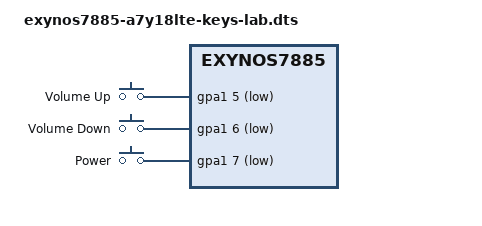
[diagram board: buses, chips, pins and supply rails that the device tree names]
// SPDX-License-Identifier: GPL-2.0
/*
 * Samsung A7 2018 Exynos7885 GPIO key mapping syntax-only research.
 *
 * All rev00/01/03 historical a7y18lte trees include the common
 * pinctrl gpa1-5 (volume up), gpa1-6 (volume down), gpa1-7 (power).
 * The modern GPIO_ACTIVE_LOW encoding follows the modern Exynos7885
 * gpio-keys binding pattern and is NOT electrically verified on SM-A750F.
 *
 * This file has no A7 RAM map or validated power rails, cannot boot,
 * and must NEVER be used for flashing.
 */
#include "exynos7885-a7y18lte-emmc-lab.dts"
#include <dt-bindings/gpio/gpio.h>
#include <dt-bindings/input/input.h>

/ {
	gpio-keys {
		compatible = "gpio-keys";
		pinctrl-names = "default";
		pinctrl-0 = <&a7_key_volup &a7_key_voldown &a7_key_power>;

		volume-up {
			label = "Volume Up";
			linux,code = <KEY_VOLUMEUP>;
			gpios = <&gpa1 5 GPIO_ACTIVE_LOW>;
		};

		volume-down {
			label = "Volume Down";
			linux,code = <KEY_VOLUMEDOWN>;
			gpios = <&gpa1 6 GPIO_ACTIVE_LOW>;
		};

		power {
			label = "Power";
			linux,code = <KEY_POWER>;
			gpios = <&gpa1 7 GPIO_ACTIVE_LOW>;
			wakeup-source;
		};
	};
};

&pinctrl_alive {
	a7_key_volup: a7-key-volup-pins {
		samsung,pins = "gpa1-5";
		samsung,pin-function = <EXYNOS_PIN_FUNC_F>;
		samsung,pin-pud = <EXYNOS_PIN_PULL_NONE>;
		samsung,pin-drv = <EXYNOS5420_PIN_DRV_LV1>;
	};

	a7_key_voldown: a7-key-voldown-pins {
		samsung,pins = "gpa1-6";
		samsung,pin-function = <EXYNOS_PIN_FUNC_F>;
		samsung,pin-pud = <EXYNOS_PIN_PULL_NONE>;
		samsung,pin-drv = <EXYNOS5420_PIN_DRV_LV1>;
	};

	a7_key_power: a7-key-power-pins {
		samsung,pins = "gpa1-7";
		samsung,pin-function = <EXYNOS_PIN_FUNC_F>;
		samsung,pin-pud = <EXYNOS_PIN_PULL_NONE>;
		samsung,pin-drv = <EXYNOS5420_PIN_DRV_LV1>;
	};
};
